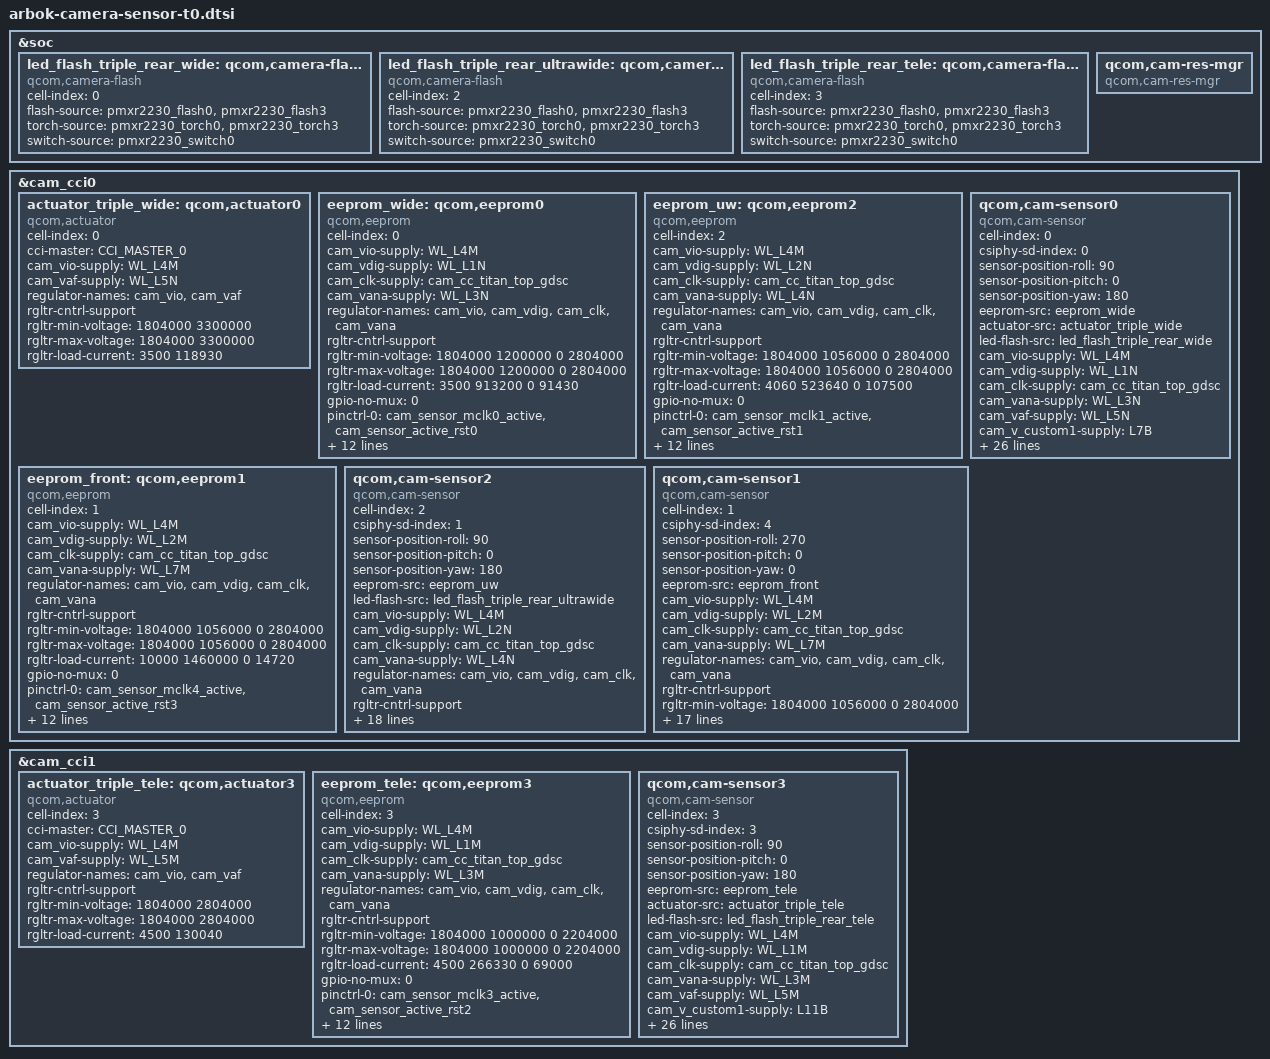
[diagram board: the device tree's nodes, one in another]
// SPDX-License-Identifier: BSD-3-Clause
/*
 * Copyright (c) 2024 Qualcomm Innovation Center, Inc. All rights reserved.
 */

#include <dt-bindings/msm-camera.h>
&soc {
	led_flash_triple_rear_wide: qcom,camera-flash0 {
		cell-index = <0>;
		compatible = "qcom,camera-flash";
		flash-source = <&pmxr2230_flash0 &pmxr2230_flash3>;
		torch-source = <&pmxr2230_torch0 &pmxr2230_torch3>;
		switch-source = <&pmxr2230_switch0>;
		status = "ok";
	};

	led_flash_triple_rear_ultrawide: qcom,camera-flash2 {
		cell-index = <2>;
		compatible = "qcom,camera-flash";
		flash-source = <&pmxr2230_flash0 &pmxr2230_flash3>;
		torch-source = <&pmxr2230_torch0 &pmxr2230_torch3>;
		switch-source = <&pmxr2230_switch0>;
		status = "ok";
	};

	led_flash_triple_rear_tele: qcom,camera-flash3 {
		cell-index = <3>;
		compatible = "qcom,camera-flash";
		flash-source = <&pmxr2230_flash0 &pmxr2230_flash3>;
		torch-source = <&pmxr2230_torch0 &pmxr2230_torch3>;
		switch-source = <&pmxr2230_switch0>;
		status = "ok";
	};

	qcom,cam-res-mgr {
		compatible = "qcom,cam-res-mgr";
		status = "ok";
	};
};

&cam_cci0 {
	actuator_triple_wide: qcom,actuator0 {
		cell-index = <0>;
		compatible = "qcom,actuator";
		cci-master = <CCI_MASTER_0>;
		cam_vio-supply = <&WL_L4M>;
		cam_vaf-supply = <&WL_L5N>;
		regulator-names = "cam_vio", "cam_vaf";
		rgltr-cntrl-support;
		rgltr-min-voltage = <1804000 3300000>;
		rgltr-max-voltage = <1804000 3300000>;
		rgltr-load-current = <3500 118930>;
		status = "ok";
	};

	eeprom_wide: qcom,eeprom0 {
		cell-index = <0>;
		compatible = "qcom,eeprom";
		cam_vio-supply = <&WL_L4M>;
		cam_vdig-supply = <&WL_L1N>;
		cam_clk-supply = <&cam_cc_titan_top_gdsc>;
		cam_vana-supply = <&WL_L3N>;
		regulator-names = "cam_vio", "cam_vdig", "cam_clk", "cam_vana";
		rgltr-cntrl-support;
		rgltr-min-voltage = <1804000 1200000 0 2804000>;
		rgltr-max-voltage = <1804000 1200000 0 2804000>;
		rgltr-load-current = <3500 913200 0 91430>;
		gpio-no-mux = <0>;
		pinctrl-names = "cam_default", "cam_suspend";
		pinctrl-0 = <&cam_sensor_mclk0_active
				 &cam_sensor_active_rst0>;
		pinctrl-1 = <&cam_sensor_mclk0_suspend
				 &cam_sensor_suspend_rst0>;
		gpios = <&tlmm 64 0>,
			<&tlmm 137 0>;
		gpio-reset = <1>;
		gpio-req-tbl-num = <0 1>;
		gpio-req-tbl-flags = <1 0>;
		gpio-req-tbl-label = "CAMIF_MCLK0",
					"CAM_RESET0";
		cci-master = <CCI_MASTER_0>;
		clocks = <&cambistmclkcc CAM_BIST_MCLK_CC_MCLK0_CLK>;
		clock-names = "cam_clk";
		clock-cntl-level = "nominal";
		clock-rates = <19200000>;
		status = "ok";
	};

	eeprom_uw: qcom,eeprom2 {
		cell-index = <2>;
		compatible = "qcom,eeprom";
		cam_vio-supply = <&WL_L4M>;
		cam_vdig-supply = <&WL_L2N>;
		cam_clk-supply = <&cam_cc_titan_top_gdsc>;
		cam_vana-supply = <&WL_L4N>;
		regulator-names = "cam_vio", "cam_vdig", "cam_clk", "cam_vana";
		rgltr-cntrl-support;
		rgltr-min-voltage = <1804000 1056000 0 2804000>;
		rgltr-max-voltage = <1804000 1056000 0 2804000>;
		rgltr-load-current = <4060 523640 0 107500>;
		gpio-no-mux = <0>;
		pinctrl-names = "cam_default", "cam_suspend";
		pinctrl-0 = <&cam_sensor_mclk1_active
				&cam_sensor_active_rst1>;
		pinctrl-1 = <&cam_sensor_mclk1_suspend
				&cam_sensor_suspend_rst1>;
		gpios = <&tlmm 65 0>,
			<&tlmm 28 0>;
		gpio-reset = <1>;
		gpio-req-tbl-num = <0 1>;
		gpio-req-tbl-flags = <1 0>;
		gpio-req-tbl-label = "CAMIF_MCLK1",
					"CAM_RESET1";
		cci-master = <CCI_MASTER_1>;
		clocks = <&cambistmclkcc CAM_BIST_MCLK_CC_MCLK1_CLK>;
		clock-names = "cam_clk";
		clock-cntl-level = "nominal";
		clock-rates = <19200000>;
		status = "ok";
	};

	eeprom_front: qcom,eeprom1 {
		cell-index = <1>;
		compatible = "qcom,eeprom";
		cam_vio-supply = <&WL_L4M>;
		cam_vdig-supply = <&WL_L2M>;
		cam_clk-supply = <&cam_cc_titan_top_gdsc>;
		cam_vana-supply = <&WL_L7M>;
		regulator-names = "cam_vio", "cam_vdig", "cam_clk", "cam_vana";
		rgltr-cntrl-support;
		rgltr-min-voltage = <1804000 1056000 0 2804000>;
		rgltr-max-voltage = <1804000 1056000 0 2804000>;
		rgltr-load-current = <10000 1460000 0 14720>;
		gpio-no-mux = <0>;
		pinctrl-names = "cam_default", "cam_suspend";
		pinctrl-0 = <&cam_sensor_mclk4_active
				 &cam_sensor_active_rst3>;
		pinctrl-1 = <&cam_sensor_mclk4_suspend
				 &cam_sensor_suspend_rst3>;
		gpios = <&tlmm 68 0>,
			<&tlmm 3 0>;
		gpio-reset = <1>;
		gpio-req-tbl-num = <0 1>;
		gpio-req-tbl-flags = <1 0>;
		gpio-req-tbl-label = "CAMIF_MCLK4",
					"CAM_RESET3";
		cci-master = <CCI_MASTER_1>;
		clocks = <&cambistmclkcc CAM_BIST_MCLK_CC_MCLK4_CLK>;
		clock-names = "cam_clk";
		clock-cntl-level = "nominal";
		clock-rates = <19200000>;
		status = "ok";
	};

	/* OV50H + OIS (Wide) */
	qcom,cam-sensor0 {
		cell-index = <0>;
		compatible = "qcom,cam-sensor";
		csiphy-sd-index = <0>;
		sensor-position-roll = <90>;
		sensor-position-pitch = <0>;
		sensor-position-yaw = <180>;
		eeprom-src = <&eeprom_wide>;
		actuator-src = <&actuator_triple_wide>;
		led-flash-src = <&led_flash_triple_rear_wide>;
		cam_vio-supply = <&WL_L4M>;
		cam_vdig-supply = <&WL_L1N>;
		cam_clk-supply = <&cam_cc_titan_top_gdsc>;
		cam_vana-supply = <&WL_L3N>;
		cam_vaf-supply = <&WL_L5N>;
		cam_v_custom1-supply = <&L7B>;
		cam_v_custom2-supply = <&WL_L7N>;
		regulator-names = "cam_vio", "cam_vdig", "cam_clk", "cam_vana",
			"cam_vaf", "cam_v_custom1", "cam_v_custom2";
		rgltr-cntrl-support;
		rgltr-min-voltage = <1804000 1200000 0 2804000 3300000 1800000 3300000>;
		rgltr-max-voltage = <1804000 1200000 0 2804000 3300000 1800000 3300000>;
		rgltr-load-current = <3500 913200 0 91430 118930 3500 118930>;
		gpio-no-mux = <0>;
		pinctrl-names = "cam_default", "cam_suspend";
		pinctrl-0 = <&cam_sensor_mclk0_active
				 &cam_sensor_active_rst0>;
		pinctrl-1 = <&cam_sensor_mclk0_suspend
				 &cam_sensor_suspend_rst0>;
		gpios = <&tlmm 64 0>,
			<&tlmm 137 0>;
		gpio-reset = <1>;
		gpio-req-tbl-num = <0 1>;
		gpio-req-tbl-flags = <1 0>;
		gpio-req-tbl-label = "CAMIF_MCLK0",
					"CAM_RESET0";
		cci-master = <CCI_MASTER_0>;
		clocks = <&cambistmclkcc CAM_BIST_MCLK_CC_MCLK0_CLK>;
		clock-names = "cam_clk";
		clock-cntl-level = "nominal";
		clock-rates = <19200000>;
		status = "ok";
	};

	/* S5KJN1 (UWide) */
	qcom,cam-sensor2 {
		cell-index = <2>;
		compatible = "qcom,cam-sensor";
		csiphy-sd-index = <1>;
		sensor-position-roll = <90>;
		sensor-position-pitch = <0>;
		sensor-position-yaw = <180>;
		eeprom-src = <&eeprom_uw>;
		led-flash-src = <&led_flash_triple_rear_ultrawide>;
		cam_vio-supply = <&WL_L4M>;
		cam_vdig-supply = <&WL_L2N>;
		cam_clk-supply = <&cam_cc_titan_top_gdsc>;
		cam_vana-supply = <&WL_L4N>;
		regulator-names = "cam_vio", "cam_vdig", "cam_clk", "cam_vana";
		rgltr-cntrl-support;
		rgltr-min-voltage = <1804000 1056000 0 2804000>;
		rgltr-max-voltage = <1804000 1056000 0 2804000>;
		rgltr-load-current = <4060 523640 0 107500>;
		gpio-no-mux = <0>;
		pinctrl-names = "cam_default", "cam_suspend";
		pinctrl-0 = <&cam_sensor_mclk1_active
				 &cam_sensor_active_rst1>;
		pinctrl-1 = <&cam_sensor_mclk1_suspend
				 &cam_sensor_suspend_rst1>;
		gpios = <&tlmm 65 0>,
			<&tlmm 28 0>;
		gpio-reset = <1>;
		gpio-req-tbl-num = <0 1>;
		gpio-req-tbl-flags = <1 0>;
		gpio-req-tbl-label = "CAMIF_MCLK1",
					"CAM_RESET1";
		cci-master = <CCI_MASTER_1>;
		clocks = <&cambistmclkcc CAM_BIST_MCLK_CC_MCLK1_CLK>;
		clock-names = "cam_clk";
		clock-cntl-level = "nominal";
		clock-rates = <19200000>;
		status = "ok";
	};

	/* S5KJN1 (Front) */
	qcom,cam-sensor1 {
		cell-index = <1>;
		compatible = "qcom,cam-sensor";
		csiphy-sd-index = <4>;
		sensor-position-roll = <270>;
		sensor-position-pitch = <0>;
		sensor-position-yaw = <0>;
		eeprom-src = <&eeprom_front>;
		cam_vio-supply = <&WL_L4M>;
		cam_vdig-supply = <&WL_L2M>;
		cam_clk-supply = <&cam_cc_titan_top_gdsc>;
		cam_vana-supply = <&WL_L7M>;
		regulator-names = "cam_vio", "cam_vdig", "cam_clk", "cam_vana";
		rgltr-cntrl-support;
		rgltr-min-voltage = <1804000 1056000 0 2804000>;
		rgltr-max-voltage = <1804000 1056000 0 2804000>;
		rgltr-load-current = <10000 1460000 0 14720>;
		gpio-no-mux = <0>;
		pinctrl-names = "cam_default", "cam_suspend";
		pinctrl-0 = <&cam_sensor_mclk4_active
				 &cam_sensor_active_rst3>;
		pinctrl-1 = <&cam_sensor_mclk4_suspend
				 &cam_sensor_suspend_rst3>;
		gpios = <&tlmm 68 0>,
			<&tlmm 3 0>;
		gpio-reset = <1>;
		gpio-req-tbl-num = <0 1>;
		gpio-req-tbl-flags = <1 0>;
		gpio-req-tbl-label = "CAMIF_MCLK4",
					"CAM_RESET3";
		cci-master = <CCI_MASTER_1>;
		clocks = <&cambistmclkcc CAM_BIST_MCLK_CC_MCLK4_CLK>;
		clock-names = "cam_clk";
		clock-cntl-level = "nominal";
		clock-rates = <19200000>;
		status = "ok";
	};
};

&cam_cci1 {
	actuator_triple_tele: qcom,actuator3{
		cell-index = <3>;
		compatible = "qcom,actuator";
		cci-master = <CCI_MASTER_0>;
		cam_vio-supply = <&WL_L4M>;
		cam_vaf-supply = <&WL_L5M>;
		regulator-names = "cam_vio", "cam_vaf";
		rgltr-cntrl-support;
		rgltr-min-voltage = <1804000 2804000>;
		rgltr-max-voltage = <1804000 2804000>;
		rgltr-load-current = <4500 130040>;
		status = "ok";
	};

	eeprom_tele: qcom,eeprom3 {
		cell-index = <3>;
		compatible = "qcom,eeprom";
		cam_vio-supply = <&WL_L4M>;
		cam_vdig-supply = <&WL_L1M>;
		cam_clk-supply = <&cam_cc_titan_top_gdsc>;
		cam_vana-supply = <&WL_L3M>;
		regulator-names = "cam_vio", "cam_vdig", "cam_clk", "cam_vana";
		rgltr-cntrl-support;
		rgltr-min-voltage = <1804000 1000000 0 2204000>;
		rgltr-max-voltage = <1804000 1000000 0 2204000>;
		rgltr-load-current = <4500 266330 0 69000>;
		gpio-no-mux = <0>;
		pinctrl-names = "cam_default", "cam_suspend";
		pinctrl-0 = <&cam_sensor_mclk3_active
				 &cam_sensor_active_rst2>;
		pinctrl-1 = <&cam_sensor_mclk3_suspend
				 &cam_sensor_suspend_rst2>;
		gpios = <&tlmm 67 0>,
			<&tlmm 180 0>;
		gpio-reset = <1>;
		gpio-req-tbl-num = <0 1>;
		gpio-req-tbl-flags = <1 0>;
		gpio-req-tbl-label = "CAMIF_MCLK3",
					"CAM_RESET2";
		cci-master = <CCI_MASTER_0>;
		clocks = <&cambistmclkcc CAM_BIST_MCLK_CC_MCLK3_CLK>;
		clock-names = "cam_clk";
		clock-cntl-level = "nominal";
		clock-rates = <19200000>;
		status = "ok";
	};

	/* S5KJN5 (Tele) */
	qcom,cam-sensor3 {
		cell-index = <3>;
		compatible = "qcom,cam-sensor";
		csiphy-sd-index = <3>;
		sensor-position-roll = <90>;
		sensor-position-pitch = <0>;
		sensor-position-yaw = <180>;
		eeprom-src = <&eeprom_tele>;
		actuator-src = <&actuator_triple_tele>;
		led-flash-src = <&led_flash_triple_rear_tele>;
		cam_vio-supply = <&WL_L4M>;
		cam_vdig-supply = <&WL_L1M>;
		cam_clk-supply = <&cam_cc_titan_top_gdsc>;
		cam_vana-supply = <&WL_L3M>;
		cam_vaf-supply = <&WL_L5M>;
		cam_v_custom1-supply = <&L11B>;
		cam_v_custom2-supply = <&WL_L6M>;
		regulator-names = "cam_vio", "cam_vdig", "cam_clk",
			"cam_vana", "cam_vaf", "cam_v_custom1", "cam_v_custom2";
		rgltr-cntrl-support;
		rgltr-min-voltage = <1804000 1000000 0 2204000 2804000 1800000 2804000>;
		rgltr-max-voltage = <1804000 1000000 0 2204000 2804000 1800000 2804000>;
		rgltr-load-current = <4500 266330 0 69000 130040 4500 130040>;
		gpio-no-mux = <0>;
		pinctrl-names = "cam_default", "cam_suspend";
		pinctrl-0 = <&cam_sensor_mclk3_active
				 &cam_sensor_active_rst2>;
		pinctrl-1 = <&cam_sensor_mclk3_suspend
				 &cam_sensor_suspend_rst2>;
		gpios = <&tlmm 67 0>,
			<&tlmm 180 0>;
		gpio-reset = <1>;
		gpio-req-tbl-num = <0 1>;
		gpio-req-tbl-flags = <1 0>;
		gpio-req-tbl-label = "CAMIF_MCLK3",
					"CAM_RESET2";
		cci-master = <CCI_MASTER_0>;
		clocks = <&cambistmclkcc CAM_BIST_MCLK_CC_MCLK3_CLK>;
		clock-names = "cam_clk";
		clock-cntl-level = "nominal";
		clock-rates = <19200000>;
		status = "ok";
	};
};
